VERSION "ks-1.0"

NS_ :

BS_:

BU_: Engine Brake Gateway

VAL_TABLE_ OnOff 0 "Off" 1 "On" ;

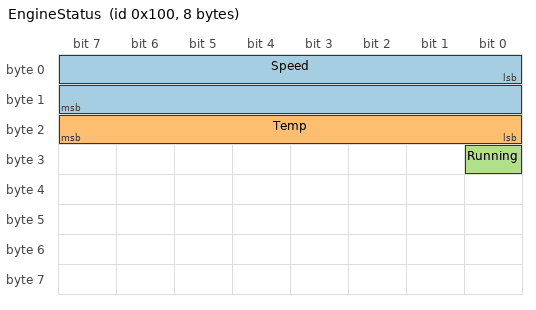
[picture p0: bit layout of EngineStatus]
BO_ 256 EngineStatus: 8 Engine
 SG_ Speed : 0|16@1+ (0.25,0) [0|8000] "rpm" Gateway
 SG_ Temp : 16|8@1- (1,-40) [-40|215] "degC" Gateway
 SG_ Running : 24|1@1+ (1,0) [0|1] "" Gateway

BO_ 300 BrakeMux: 8 Brake
 SG_ Mode M : 0|4@1+ (1,0) [0|15] "" Gateway
 SG_ Pressure m0 : 8|16@1+ (0.1,0) [0|6553.5] "bar" Gateway
 SG_ PedalPct m1 : 8|8@1+ (1,0) [0|100] "%" Gateway

BO_ 2147484160 DiagRequest: 8 Gateway
 SG_ Service : 0|8@1+ (1,0) [0|255] "" Vector__XXX
 SG_ Value : 8|32@1+ (1,0) [0|4294967295] "" Vector__XXX

BO_TX_BU_ 256 : Engine,Gateway;

EV_ RigTime: 1 [0|86400] "s" 0 1 DUMMY_NODE_VECTOR0 Gateway;

CM_ "Kitchen-sink DBC used by aletheia B.3 corpus.";
CM_ BU_ Engine "Primary engine ECU.";
CM_ BO_ 256 "Periodic engine status.";
CM_ SG_ 256 Temp "Coolant temperature, -40 offset encoding.";
CM_ EV_ RigTime "Wall-clock seconds on the test rig.";

BA_DEF_ "BusType" STRING ;
BA_DEF_ BU_  "NodeLoad" FLOAT 0 100;
BA_DEF_ BO_  "GenMsgCycleTime" INT 0 10000;
BA_DEF_ SG_  "SignalPriority" ENUM  "Low","Normal","High";
BA_DEF_ EV_  "EnvScaling" HEX 0 255;
BA_DEF_REL_ BU_BO_REL_  "NodeMsgRole" INT 0 3;
BA_DEF_REL_ BU_SG_REL_  "NodeSigRole" INT 0 1;
BA_DEF_DEF_  "BusType" "CAN";
BA_DEF_DEF_  "NodeLoad" 0;
BA_DEF_DEF_  "GenMsgCycleTime" 100;
BA_DEF_DEF_  "SignalPriority" "Normal";
BA_DEF_DEF_  "EnvScaling" 1;
BA_DEF_DEF_  "NodeMsgRole" 0;
BA_DEF_DEF_  "NodeSigRole" 0;

BA_ "NodeLoad" BU_ Engine 12.5;
BA_ "GenMsgCycleTime" BO_ 256 10;
BA_ "SignalPriority" SG_ 256 Speed 2;
BA_REL_ "NodeMsgRole" BU_BO_REL_ Gateway 256 1;
BA_REL_ "NodeSigRole" BU_SG_REL_ Gateway SG_ 256 Speed 1;

VAL_ 256 Running 0 "Stopped" 1 "Running" ;

SIG_GROUP_ 256 StatusGroup 1 : Speed Temp Running;

SIG_VALTYPE_ 256 Speed : 1;

SG_MUL_VAL_ 300 Pressure Mode 0-0;
SG_MUL_VAL_ 300 PedalPct Mode 1-1;
